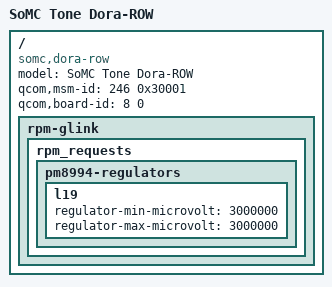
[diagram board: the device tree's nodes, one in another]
// SPDX-License-Identifier: GPL-2.0
/* Copyright (C) 2016 Sony Mobile Communications Inc.
 * Copyright (c) 2019 AngeloGioacchino Del Regno <kholk11@gmail.com>
 */

/dts-v1/;

#include "msm8996-sony-xperia-tone.dtsi"

/ {
	model = "SoMC Tone Dora-ROW";
	compatible = "somc,dora-row", "qcom,msm8996";

	qcom,msm-id = <246 0x30001>;
	qcom,board-id = <8 0>;

	rpm-glink {
		rpm_requests {
			pm8994-regulators {
				l19 {
					regulator-min-microvolt = <3000000>;
					regulator-max-microvolt = <3000000>;
				};
			};
		};
	};
};

